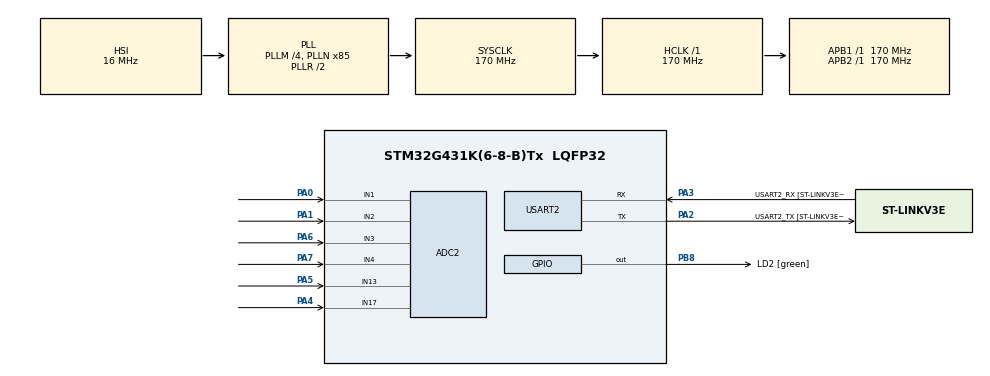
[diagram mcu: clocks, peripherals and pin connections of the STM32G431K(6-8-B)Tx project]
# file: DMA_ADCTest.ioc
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ADC2.Channel-0\#ChannelRegularConversion=ADC_CHANNEL_1
ADC2.Channel-1\#ChannelRegularConversion=ADC_CHANNEL_2
ADC2.Channel-2\#ChannelRegularConversion=ADC_CHANNEL_3
ADC2.Channel-3\#ChannelRegularConversion=ADC_CHANNEL_4
ADC2.Channel-4\#ChannelRegularConversion=ADC_CHANNEL_13
ADC2.Channel-5\#ChannelRegularConversion=ADC_CHANNEL_17
ADC2.ContinuousConvMode=ENABLE
ADC2.DMAContinuousRequests=ENABLE
ADC2.NbrOfConversion=6
ADC2.NbrOfConversionFlag=1
ADC2.OffsetNumber-0\#ChannelRegularConversion=ADC_OFFSET_NONE
ADC2.OffsetNumber-1\#ChannelRegularConversion=ADC_OFFSET_NONE
ADC2.OffsetNumber-2\#ChannelRegularConversion=ADC_OFFSET_NONE
ADC2.OffsetNumber-3\#ChannelRegularConversion=ADC_OFFSET_NONE
ADC2.OffsetNumber-4\#ChannelRegularConversion=ADC_OFFSET_NONE
ADC2.OffsetNumber-5\#ChannelRegularConversion=ADC_OFFSET_NONE
ADC2.Rank-0\#ChannelRegularConversion=1
ADC2.Rank-1\#ChannelRegularConversion=2
ADC2.Rank-2\#ChannelRegularConversion=3
ADC2.Rank-3\#ChannelRegularConversion=4
ADC2.Rank-4\#ChannelRegularConversion=5
ADC2.Rank-5\#ChannelRegularConversion=6
ADC2.SamplingTime-0\#ChannelRegularConversion=ADC_SAMPLETIME_2CYCLES_5
ADC2.SamplingTime-1\#ChannelRegularConversion=ADC_SAMPLETIME_2CYCLES_5
ADC2.SamplingTime-2\#ChannelRegularConversion=ADC_SAMPLETIME_2CYCLES_5
ADC2.SamplingTime-3\#ChannelRegularConversion=ADC_SAMPLETIME_2CYCLES_5
ADC2.SamplingTime-4\#ChannelRegularConversion=ADC_SAMPLETIME_2CYCLES_5
ADC2.SamplingTime-5\#ChannelRegularConversion=ADC_SAMPLETIME_2CYCLES_5
Dma.ADC2.0.Direction=DMA_PERIPH_TO_MEMORY
Dma.ADC2.0.EventEnable=DISABLE
Dma.ADC2.0.Instance=DMA1_Channel1
Dma.ADC2.0.MemDataAlignment=DMA_MDATAALIGN_HALFWORD
Dma.ADC2.0.MemInc=DMA_MINC_ENABLE
Dma.ADC2.0.Mode=DMA_CIRCULAR
Dma.ADC2.0.PeriphDataAlignment=DMA_PDATAALIGN_HALFWORD
Dma.ADC2.0.PeriphInc=DMA_PINC_DISABLE
Dma.ADC2.0.Polarity=HAL_DMAMUX_REQ_GEN_RISING
Dma.ADC2.0.Priority=DMA_PRIORITY_MEDIUM
Dma.ADC2.0.RequestNumber=1
Dma.ADC2.0.SignalID=NONE
Dma.ADC2.0.SyncEnable=DISABLE
Dma.ADC2.0.SyncPolarity=HAL_DMAMUX_SYNC_NO_EVENT
Dma.ADC2.0.SyncRequestNumber=1
Dma.ADC2.0.SyncSignalID=NONE
Dma.Request0=ADC2
Mcu.Family=STM32G4
Mcu.Name=STM32G431K(6-8-B)Tx
Mcu.Package=LQFP32
NVIC.DMA1_Channel1_IRQn=true\:0\:0\:false\:false\:true\:false\:true\:true
NVIC.PriorityGroup=NVIC_PRIORITYGROUP_4
PA0.Mode=IN1-Single-Ended
PA0.Signal=ADC2_IN1
PA1.Mode=IN2-Single-Ended
PA1.Signal=ADC2_IN2
PA13.GPIO_Label=T_SWDIO
PA13.Mode=Serial_Wire
PA13.Signal=SYS_JTMS-SWDIO
PA14.GPIO_Label=T_SWCLK
PA14.Mode=Serial_Wire
PA14.Signal=SYS_JTCK-SWCLK
PA2.GPIO_Label=USART2_TX [ST-LINKV3E_VCP_RX]
PA2.Mode=Asynchronous
PA2.Signal=USART2_TX
PA3.GPIO_Label=USART2_RX [ST-LINKV3E_VCP_TX]
PA3.Mode=Asynchronous
PA3.Signal=USART2_RX
PA4.Mode=IN17-Single-Ended
PA4.Signal=ADC2_IN17
PA5.Mode=IN13-Single-Ended
PA5.Signal=ADC2_IN13
PA6.Mode=IN3-Single-Ended
PA6.Signal=ADC2_IN3
PA7.Mode=IN4-Single-Ended
PA7.Signal=ADC2_IN4
PB3.GPIO_Label=T_SWO
PB3.Signal=SYS_JTDO-SWO
PB8-BOOT0.GPIO_Label=LD2 [green]
PB8-BOOT0.Signal=GPIO_Output
ProjectManager.HeapSize=0x200
ProjectManager.StackSize=0x400
ProjectManager.TargetToolchain=STM32CubeIDE
RCC.ADC12Freq_Value=170000000
RCC.AHBFreq_Value=170000000
RCC.APB1Freq_Value=170000000
RCC.APB1TimFreq_Value=170000000
RCC.APB2Freq_Value=170000000
RCC.APB2TimFreq_Value=170000000
RCC.CortexFreq_Value=170000000
RCC.EXTERNAL_CLOCK_VALUE=12288000
RCC.HCLKFreq_Value=170000000
RCC.HSE_VALUE=8000000
RCC.HSI48_VALUE=48000000
RCC.HSI_VALUE=16000000
RCC.LSE_VALUE=32768
RCC.PLLM=RCC_PLLM_DIV4
RCC.PLLN=85
RCC.SYSCLKFreq_VALUE=170000000
RCC.SYSCLKSource=RCC_SYSCLKSOURCE_PLLCLK
RCC.USBFreq_Value=170000000
RCC.VCOOutputFreq_Value=340000000
USART2.VirtualMode-Asynchronous=VM_ASYNC
USART2.WordLength=WORDLENGTH_8B
board=NUCLEO-G431KB

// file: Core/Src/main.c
/* USER CODE BEGIN Header */
/**
  ******************************************************************************
  * @file           : main.c
  * @brief          : Main program body
  ******************************************************************************
  * @attention
  *
  * Copyright (c) 2022 STMicroelectronics.
  * All rights reserved.
  *
  * This software is licensed under terms that can be found in the LICENSE file
  * in the root directory of this software component.
  * If no LICENSE file comes with this software, it is provided AS-IS.
  *
  ******************************************************************************
  */
/* USER CODE END Header */
#include "main.h"
#include <stdio.h>

ADC_HandleTypeDef hadc2;
DMA_HandleTypeDef hdma_adc2;

UART_HandleTypeDef huart2;

void SystemClock_Config(void);
static void MX_GPIO_Init(void);
static void MX_DMA_Init(void);
static void MX_USART2_UART_Init(void);
static void MX_ADC2_Init(void);

/* USER CODE BEGIN 0 */
uint32_t gu_temp =0;
uint32_t distance[6] = {};
uint32_t gu_dma[7];

void adc_test(void){
	HAL_ADCEx_Calibration_Start(&hadc2, ADC_SINGLE_ENDED);
	HAL_ADC_Start_DMA(&hadc2, (uint32_t*)gu_dma, 7);
	while(1){
			for(int i=0; i<7; i++){
			//DMABuf[i] = gu_dma[i+1];

		}
	}
}
/* USER CODE END 0 */

int main(void)
{
  /* USER CODE BEGIN 1 */
	setbuf(stdout, NULL);
  /* USER CODE END 1 */

  /* MCU Configuration--------------------------------------------------------*/

  /* Reset of all peripherals, Initializes the Flash interface and the Systick. */
  HAL_Init();

  /* Configure the system clock */
  SystemClock_Config();

  /* Initialize all configured peripherals */
  MX_GPIO_Init();
  MX_DMA_Init();
  MX_USART2_UART_Init();
  MX_ADC2_Init();
  /* USER CODE BEGIN 2 */
  //adc_test();
  HAL_ADCEx_Calibration_Start(&hadc2, ADC_SINGLE_ENDED);
  HAL_ADC_Start_DMA(&hadc2, (uint32_t*)gu_dma, 7);

  uint8_t buff[10];
  /* USER CODE END 2 */

  /* Infinite loop */
  /* USER CODE BEGIN WHILE */
  while (1)
  {

    /* USER CODE BEGIN 3 */
	  /* USER CODE END WHILE */
	  	  /*for(int i=0; i<7; i++){
	  			//DMABuf[i] = gu_dma[i+1];
	  			printf("Sensor%d: %ld", i, gu_dma[i+1]);
	  	  }*/
	  	  //printf("hello world");
	  for(int i=0; i<7; i++){
	  	snprintf(buff, sizeof(buff), "%d", gu_dma[i+1]);
	  	HAL_UART_Transmit(&huart2, buff, sizeof(buff), 100);
	  }
  }
  /* USER CODE END 3 */
}

void SystemClock_Config(void)
{
  RCC_OscInitTypeDef RCC_OscInitStruct = {0};
  RCC_ClkInitTypeDef RCC_ClkInitStruct = {0};

  /** Configure the main internal regulator output voltage
  */
  HAL_PWREx_ControlVoltageScaling(PWR_REGULATOR_VOLTAGE_SCALE1_BOOST);

  /** Initializes the RCC Oscillators according to the specified parameters
  * in the RCC_OscInitTypeDef structure.
  */
  RCC_OscInitStruct.OscillatorType = RCC_OSCILLATORTYPE_HSI;
  RCC_OscInitStruct.HSIState = RCC_HSI_ON;
  RCC_OscInitStruct.HSICalibrationValue = RCC_HSICALIBRATION_DEFAULT;
  RCC_OscInitStruct.PLL.PLLState = RCC_PLL_ON;
  RCC_OscInitStruct.PLL.PLLSource = RCC_PLLSOURCE_HSI;
  RCC_OscInitStruct.PLL.PLLM = RCC_PLLM_DIV4;
  RCC_OscInitStruct.PLL.PLLN = 85;
  RCC_OscInitStruct.PLL.PLLP = RCC_PLLP_DIV2;
  RCC_OscInitStruct.PLL.PLLQ = RCC_PLLQ_DIV2;
  RCC_OscInitStruct.PLL.PLLR = RCC_PLLR_DIV2;
  if (HAL_RCC_OscConfig(&RCC_OscInitStruct) != HAL_OK)
  {
    Error_Handler();
  }

  /** Initializes the CPU, AHB and APB buses clocks
  */
  RCC_ClkInitStruct.ClockType = RCC_CLOCKTYPE_HCLK|RCC_CLOCKTYPE_SYSCLK
                              |RCC_CLOCKTYPE_PCLK1|RCC_CLOCKTYPE_PCLK2;
  RCC_ClkInitStruct.SYSCLKSource = RCC_SYSCLKSOURCE_PLLCLK;
  RCC_ClkInitStruct.AHBCLKDivider = RCC_SYSCLK_DIV1;
  RCC_ClkInitStruct.APB1CLKDivider = RCC_HCLK_DIV1;
  RCC_ClkInitStruct.APB2CLKDivider = RCC_HCLK_DIV1;

  if (HAL_RCC_ClockConfig(&RCC_ClkInitStruct, FLASH_LATENCY_4) != HAL_OK)
  {
    Error_Handler();
  }
}

static void MX_ADC2_Init(void)
{

  ADC_ChannelConfTypeDef sConfig = {0};

  /** Common config
  */
  hadc2.Instance = ADC2;
  hadc2.Init.ClockPrescaler = ADC_CLOCK_SYNC_PCLK_DIV4;
  hadc2.Init.Resolution = ADC_RESOLUTION_12B;
  hadc2.Init.DataAlign = ADC_DATAALIGN_RIGHT;
  hadc2.Init.GainCompensation = 0;
  hadc2.Init.ScanConvMode = ADC_SCAN_ENABLE;
  hadc2.Init.EOCSelection = ADC_EOC_SINGLE_CONV;
  hadc2.Init.LowPowerAutoWait = DISABLE;
  hadc2.Init.ContinuousConvMode = ENABLE;
  hadc2.Init.NbrOfConversion = 6;
  hadc2.Init.DiscontinuousConvMode = DISABLE;
  hadc2.Init.ExternalTrigConv = ADC_SOFTWARE_START;
  hadc2.Init.ExternalTrigConvEdge = ADC_EXTERNALTRIGCONVEDGE_NONE;
  hadc2.Init.DMAContinuousRequests = ENABLE;
  hadc2.Init.Overrun = ADC_OVR_DATA_PRESERVED;
  hadc2.Init.OversamplingMode = DISABLE;
  if (HAL_ADC_Init(&hadc2) != HAL_OK)
  {
    Error_Handler();
  }

  /** Configure Regular Channel
  */
  sConfig.Channel = ADC_CHANNEL_1;
  sConfig.Rank = ADC_REGULAR_RANK_1;
  sConfig.SamplingTime = ADC_SAMPLETIME_2CYCLES_5;
  sConfig.SingleDiff = ADC_SINGLE_ENDED;
  sConfig.OffsetNumber = ADC_OFFSET_NONE;
  sConfig.Offset = 0;
  if (HAL_ADC_ConfigChannel(&hadc2, &sConfig) != HAL_OK)
  {
    Error_Handler();
  }

  /** Configure Regular Channel
  */
  sConfig.Channel = ADC_CHANNEL_2;
  sConfig.Rank = ADC_REGULAR_RANK_2;
  if (HAL_ADC_ConfigChannel(&hadc2, &sConfig) != HAL_OK)
  {
    Error_Handler();
  }

  /** Configure Regular Channel
  */
  sConfig.Channel = ADC_CHANNEL_3;
  sConfig.Rank = ADC_REGULAR_RANK_3;
  if (HAL_ADC_ConfigChannel(&hadc2, &sConfig) != HAL_OK)
  {
    Error_Handler();
  }

  /** Configure Regular Channel
  */
  sConfig.Channel = ADC_CHANNEL_4;
  sConfig.Rank = ADC_REGULAR_RANK_4;
  if (HAL_ADC_ConfigChannel(&hadc2, &sConfig) != HAL_OK)
  {
    Error_Handler();
  }

  /** Configure Regular Channel
  */
  sConfig.Channel = ADC_CHANNEL_13;
  sConfig.Rank = ADC_REGULAR_RANK_5;
  if (HAL_ADC_ConfigChannel(&hadc2, &sConfig) != HAL_OK)
  {
    Error_Handler();
  }

  /** Configure Regular Channel
  */
  sConfig.Channel = ADC_CHANNEL_17;
  sConfig.Rank = ADC_REGULAR_RANK_6;
  if (HAL_ADC_ConfigChannel(&hadc2, &sConfig) != HAL_OK)
  {
    Error_Handler();
  }

}

static void MX_USART2_UART_Init(void)
{

  huart2.Instance = USART2;
  huart2.Init.BaudRate = 115200;
  huart2.Init.WordLength = UART_WORDLENGTH_8B;
  huart2.Init.StopBits = UART_STOPBITS_1;
  huart2.Init.Parity = UART_PARITY_NONE;
  huart2.Init.Mode = UART_MODE_TX_RX;
  huart2.Init.HwFlowCtl = UART_HWCONTROL_NONE;
  huart2.Init.OverSampling = UART_OVERSAMPLING_16;
  huart2.Init.OneBitSampling = UART_ONE_BIT_SAMPLE_DISABLE;
  huart2.Init.ClockPrescaler = UART_PRESCALER_DIV1;
  huart2.AdvancedInit.AdvFeatureInit = UART_ADVFEATURE_NO_INIT;
  if (HAL_UART_Init(&huart2) != HAL_OK)
  {
    Error_Handler();
  }
  if (HAL_UARTEx_SetTxFifoThreshold(&huart2, UART_TXFIFO_THRESHOLD_1_8) != HAL_OK)
  {
    Error_Handler();
  }
  if (HAL_UARTEx_SetRxFifoThreshold(&huart2, UART_RXFIFO_THRESHOLD_1_8) != HAL_OK)
  {
    Error_Handler();
  }
  if (HAL_UARTEx_DisableFifoMode(&huart2) != HAL_OK)
  {
    Error_Handler();
  }

}

static void MX_DMA_Init(void)
{

  /* DMA controller clock enable */
  __HAL_RCC_DMAMUX1_CLK_ENABLE();
  __HAL_RCC_DMA1_CLK_ENABLE();

  /* DMA interrupt init */
  /* DMA1_Channel1_IRQn interrupt configuration */
  HAL_NVIC_SetPriority(DMA1_Channel1_IRQn, 0, 0);
  HAL_NVIC_EnableIRQ(DMA1_Channel1_IRQn);

}

static void MX_GPIO_Init(void)
{
  GPIO_InitTypeDef GPIO_InitStruct = {0};

  /* GPIO Ports Clock Enable */
  __HAL_RCC_GPIOA_CLK_ENABLE();
  __HAL_RCC_GPIOB_CLK_ENABLE();

  /*Configure GPIO pin Output Level */
  HAL_GPIO_WritePin(LD2_GPIO_Port, LD2_Pin, GPIO_PIN_RESET);

  /*Configure GPIO pin : LD2_Pin */
  GPIO_InitStruct.Pin = LD2_Pin;
  GPIO_InitStruct.Mode = GPIO_MODE_OUTPUT_PP;
  GPIO_InitStruct.Pull = GPIO_NOPULL;
  GPIO_InitStruct.Speed = GPIO_SPEED_FREQ_LOW;
  HAL_GPIO_Init(LD2_GPIO_Port, &GPIO_InitStruct);

}

void Error_Handler(void)
{
  __disable_irq();
  while (1)
  {
  }
}
